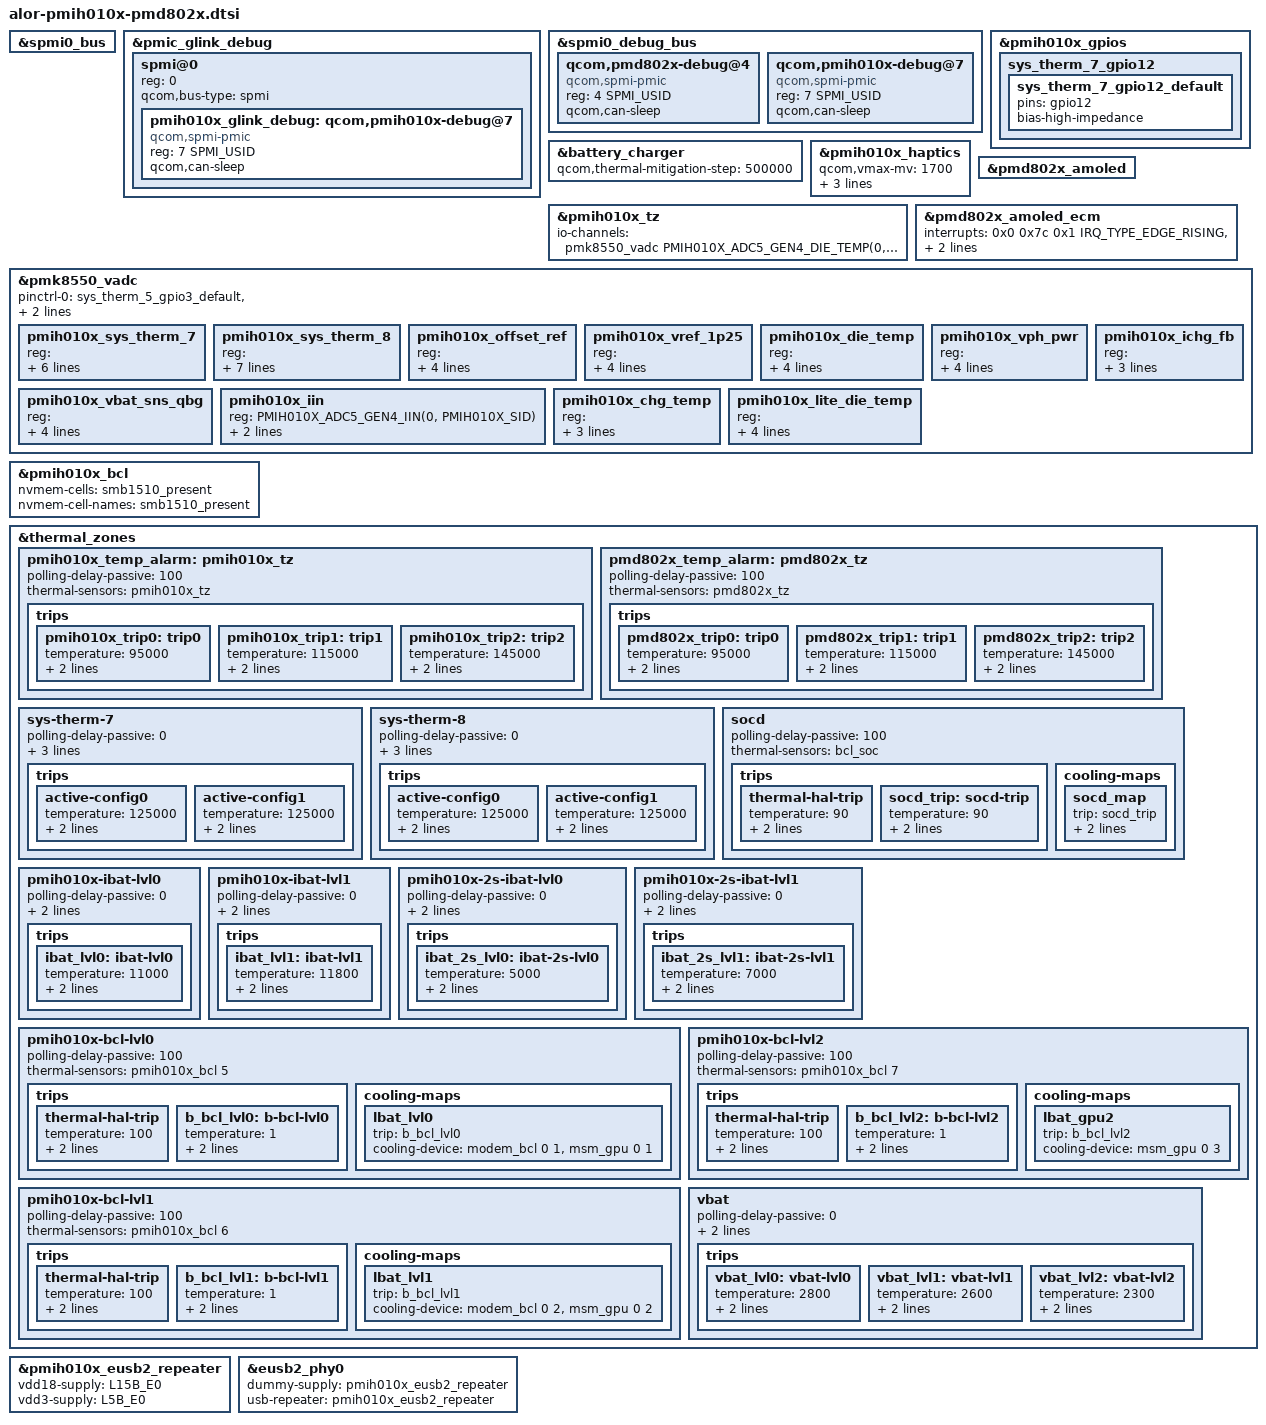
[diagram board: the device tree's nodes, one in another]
// SPDX-License-Identifier: BSD-3-Clause
/*
 * Copyright (c) Qualcomm Technologies, Inc. and/or its subsidiaries.
 */

#include <dt-bindings/iio/qcom,spmi-vadc.h>
#include <dt-bindings/iio/qcom,spmi-adc5-gen4-pmih010x.h>

#define PMIH010X_SID	7

&spmi0_bus {
	#include "pmih010x.dtsi"
	#include "pmd802x.dtsi"
};

&pmic_glink_debug {
	spmi@0 {
		reg = <0>;
		#address-cells = <2>;
		#size-cells = <0>;
		qcom,bus-type = "spmi";

		pmih010x_glink_debug: qcom,pmih010x-debug@7 {
			compatible = "qcom,spmi-pmic";
			reg = <7 SPMI_USID>;
			qcom,can-sleep;
		};
	};
};

&spmi0_debug_bus {
	qcom,pmd802x-debug@4 {
		compatible = "qcom,spmi-pmic";
		reg = <4 SPMI_USID>;
		#address-cells = <2>;
		#size-cells = <0>;
		qcom,can-sleep;
	};

	qcom,pmih010x-debug@7 {
		compatible = "qcom,spmi-pmic";
		reg = <7 SPMI_USID>;
		#address-cells = <2>;
		#size-cells = <0>;
		qcom,can-sleep;
	};
};

&pmih010x_gpios {
	sys_therm_7_gpio12 {
		sys_therm_7_gpio12_default: sys_therm_7_gpio12_default {
			pins = "gpio12";
			bias-high-impedance;
		};
	};
};

&battery_charger {
	qcom,thermal-mitigation-step = <500000>;
	#cooling-cells = <2>;
};

&pmih010x_haptics {
	qcom,vmax-mv = <1700>;
	qcom,lra-period-us = <5880>;
	nvmem-names = "hap_cfg_sdam";
	nvmem = <&pmk8550_sdam_46>;
};

&pmih010x_tz {
	io-channels = <&pmk8550_vadc PMIH010X_ADC5_GEN4_DIE_TEMP(0, PMIH010X_SID)>;
	io-channel-names = "thermal";
};

&pmd802x_amoled {
	status = "ok";
};

&pmd802x_amoled_ecm {
	interrupts = <0x0 0x7c 0x1 IRQ_TYPE_EDGE_RISING>,
		     <0x0 0x7d 0x1 IRQ_TYPE_EDGE_RISING>,
		     <0x0 0x98 0x1 IRQ_TYPE_EDGE_RISING>;
};

&pmk8550_vadc {
	pinctrl-0 = <&sys_therm_5_gpio3_default>,
			<&sys_therm_12_gpio2_default>,
			<&sys_therm_7_gpio12_default>;
	pinctrl-names = "default";

	pmih010x_sys_therm_7 {
		reg = <PMIH010X_ADC5_GEN4_AMUX4_GPIO12_100K_PU(0, PMIH010X_SID)>;
		label = "pmih010x_sys_therm_7";
		qcom,ratiometric;
		qcom,pre-scaling = <1 1>;
		qcom,adc-tm-type = <1>;
		qcom,adc5-gen4;
	};

	pmih010x_sys_therm_8 {
		reg = <PMIH010X_ADC5_GEN4_AMUX_THM4_USB_THERM_100K_PU(0, PMIH010X_SID)>;
		label = "pmih010x_sys_therm_8";
		qcom,ratiometric;
		qcom,hw-settle-time = <200>;
		qcom,pre-scaling = <1 1>;
		qcom,adc-tm-type = <1>;
		qcom,adc5-gen4;
	};

	pmih010x_offset_ref {
		reg = <PMIH010X_ADC5_GEN4_OFFSET_REF(0, PMIH010X_SID)>;
		label = "pmih010x_offset_ref";
		qcom,pre-scaling = <1 1>;
		qcom,adc5-gen4;
	};

	pmih010x_vref_1p25 {
		reg = <PMIH010X_ADC5_GEN4_1P25VREF(0, PMIH010X_SID)>;
		label = "pmih010x_vref_1p25";
		qcom,pre-scaling = <1 1>;
		qcom,adc5-gen4;
	};

	pmih010x_die_temp {
		reg = <PMIH010X_ADC5_GEN4_DIE_TEMP(0, PMIH010X_SID)>;
		label = "pmih010x_die_temp";
		qcom,pre-scaling = <1 1>;
		qcom,adc5-gen4;
	};

	pmih010x_vph_pwr {
		reg = <PMIH010X_ADC5_GEN4_VPH_PWR(0, PMIH010X_SID)>;
		label = "pmih010x_vph_pwr";
		qcom,pre-scaling = <1 3>;
		qcom,adc5-gen4;
	};

	pmih010x_vbat_sns_qbg {
		reg = <PMIH010X_ADC5_GEN4_VBAT_SNS_QBG(0, PMIH010X_SID)>;
		label = "pmih010x_vbat_sns_qbg";
		qcom,pre-scaling = <1 3>;
		qcom,adc5-gen4;
	};

	pmih010x_iin {
		reg = <PMIH010X_ADC5_GEN4_IIN(0, PMIH010X_SID)>;
		label = "pmih010x_iin";
		qcom,adc5-gen4;
	};

	pmih010x_ichg_fb {
		reg = <PMIH010X_ADC5_GEN4_ICHG_FB(0, PMIH010X_SID)>;
		label = "pmih010x_ichg_fb";
		qcom,adc5-gen4;
	};

	pmih010x_chg_temp {
		reg = <PMIH010X_ADC5_GEN4_CHG_TEMP(0, PMIH010X_SID)>;
		label = "pmih010x_chg_temp";
		qcom,adc5-gen4;
	};

	pmih010x_lite_die_temp {
		reg = <PMIH010X_ADC5_GEN4_TEMP_ALARM_LITE(0, PMIH010X_SID)>;
		label = "pmih010x_lite_die_temp";
		qcom,pre-scaling = <1 1>;
		qcom,adc5-gen4;
	};
};

&pmih010x_bcl {
	nvmem-cells = <&smb1510_present>;
	nvmem-cell-names = "smb1510_present";
};

&thermal_zones {
	pmih010x_temp_alarm: pmih010x_tz {
		polling-delay-passive = <100>;
		thermal-sensors = <&pmih010x_tz>;

		trips {
			pmih010x_trip0: trip0 {
				temperature = <95000>;
				hysteresis = <0>;
				type = "passive";
			};

			pmih010x_trip1: trip1 {
				temperature = <115000>;
				hysteresis = <0>;
				type = "hot";
			};

			pmih010x_trip2: trip2 {
				temperature = <145000>;
				hysteresis = <0>;
				type = "critical";
			};
		};
	};

	pmd802x_temp_alarm: pmd802x_tz {
		polling-delay-passive = <100>;
		thermal-sensors = <&pmd802x_tz>;

		trips {
			pmd802x_trip0: trip0 {
				temperature = <95000>;
				hysteresis = <0>;
				type = "passive";
			};

			pmd802x_trip1: trip1 {
				temperature = <115000>;
				hysteresis = <0>;
				type = "hot";
			};

			pmd802x_trip2: trip2 {
				temperature = <145000>;
				hysteresis = <0>;
				type = "critical";
			};
		};
	};

	sys-therm-7 {
		polling-delay-passive = <0>;
		polling-delay = <0>;
		thermal-sensors = <&pmk8550_vadc PMIH010X_ADC5_GEN4_AMUX4_GPIO12_100K_PU(0, PMIH010X_SID)>;
		trips {
			active-config0 {
				temperature = <125000>;
				hysteresis = <1000>;
				type = "passive";
			};

			active-config1 {
				temperature = <125000>;
				hysteresis = <1000>;
				type = "passive";
			};
		};
	};

	sys-therm-8 {
		polling-delay-passive = <0>;
		polling-delay = <0>;
		thermal-sensors = <&pmk8550_vadc PMIH010X_ADC5_GEN4_AMUX_THM4_USB_THERM_100K_PU(0, PMIH010X_SID)>;
		trips {
			active-config0 {
				temperature = <125000>;
				hysteresis = <1000>;
				type = "passive";
			};

			active-config1 {
				temperature = <125000>;
				hysteresis = <1000>;
				type = "passive";
			};
		};
	};

	socd {
		polling-delay-passive = <100>;
		thermal-sensors = <&bcl_soc>;

		trips {
			thermal-hal-trip {
				temperature = <90>;
				hysteresis = <0>;
				type = "passive";
			};

			socd_trip: socd-trip {
				temperature = <90>;
				hysteresis = <0>;
				type = "passive";
			};
		};

		cooling-maps {
			socd_map {
				trip = <&socd_trip>;
				cooling-device = <&APC1_MX_CX_PAUSE 0 1>,
					<&cdsp_sw 0 4>,
					<&msm_gpu 0 4>;
			};
		};
	};

	pmih010x-ibat-lvl0 {
		polling-delay-passive = <0>;
		polling-delay = <0>;
		thermal-sensors = <&pmih010x_bcl 0>;

		trips {
			ibat_lvl0:ibat-lvl0 {
				temperature = <11000>;
				hysteresis = <200>;
				type = "passive";
			};
		};
	};

	pmih010x-ibat-lvl1 {
		polling-delay-passive = <0>;
		polling-delay = <0>;
		thermal-sensors = <&pmih010x_bcl 1>;

		trips {
			ibat_lvl1:ibat-lvl1 {
				temperature = <11800>;
				hysteresis = <200>;
				type = "passive";
			};
		};
	};

	pmih010x-2s-ibat-lvl0 {
		polling-delay-passive = <0>;
		polling-delay = <0>;
		thermal-sensors = <&pmih010x_bcl 8>;

		trips {
			ibat_2s_lvl0: ibat-2s-lvl0 {
				temperature = <5000>;
				hysteresis = <200>;
				type = "passive";
			};
		};
	};

	pmih010x-2s-ibat-lvl1 {
		polling-delay-passive = <0>;
		polling-delay = <0>;
		thermal-sensors = <&pmih010x_bcl 9>;

		trips {
			ibat_2s_lvl1: ibat-2s-lvl1 {
				temperature = <7000>;
				hysteresis = <200>;
				type = "passive";
			};
		};
	};

	pmih010x-bcl-lvl0 {
		polling-delay-passive = <100>;
		thermal-sensors = <&pmih010x_bcl 5>;

		trips {
			thermal-hal-trip {
				temperature = <100>;
				hysteresis = <0>;
				type = "passive";
			};

			b_bcl_lvl0: b-bcl-lvl0 {
				temperature = <1>;
				hysteresis = <0>;
				type = "passive";
			};
		};

		cooling-maps {
			lbat_lvl0 {
				trip = <&b_bcl_lvl0>;
				cooling-device = <&modem_bcl 0 1>,
					<&msm_gpu 0 1>;
			};
		};
	};

	pmih010x-bcl-lvl1 {
		polling-delay-passive = <100>;
		thermal-sensors = <&pmih010x_bcl 6>;

		trips {
			thermal-hal-trip {
				temperature = <100>;
				hysteresis = <0>;
				type = "passive";
			};

			b_bcl_lvl1: b-bcl-lvl1 {
				temperature = <1>;
				hysteresis = <0>;
				type = "passive";
			};
		};

		cooling-maps {
			lbat_lvl1 {
				trip = <&b_bcl_lvl1>;
				cooling-device = <&modem_bcl 0 2>,
					<&msm_gpu 0 2>;
			};
		};
	};

	pmih010x-bcl-lvl2 {
		polling-delay-passive = <100>;
		thermal-sensors = <&pmih010x_bcl 7>;

		trips {
			thermal-hal-trip {
				temperature = <100>;
				hysteresis = <0>;
				type = "passive";
			};

			b_bcl_lvl2: b-bcl-lvl2 {
				temperature = <1>;
				hysteresis = <0>;
				type = "passive";
			};
		};

		cooling-maps {
			lbat_gpu2 {
				trip = <&b_bcl_lvl2>;
				cooling-device = <&msm_gpu 0 3>;
			};
		};
	};

	vbat {
		polling-delay-passive = <0>;
		polling-delay = <0>;
		thermal-sensors = <&pmih010x_bcl 2>;

		trips {
			vbat_lvl0:vbat-lvl0 {
				temperature = <2800>;
				hysteresis = <100>;
				type = "passive";
			};

			vbat_lvl1:vbat-lvl1 {
				temperature = <2600>;
				hysteresis = <100>;
				type = "passive";
			};

			vbat_lvl2:vbat-lvl2 {
				temperature = <2300>;
				hysteresis = <100>;
				type = "passive";
			};
		};
	};
};

&pmih010x_eusb2_repeater {
	status = "ok";
	vdd18-supply = <&L15B_E0>;
	vdd3-supply = <&L5B_E0>;
};

&eusb2_phy0 {
	dummy-supply = <&pmih010x_eusb2_repeater>;
	usb-repeater = <&pmih010x_eusb2_repeater>;
};
